AUTOSAR XML (schema 00044)
package /E40_Platform_System_SystemPackage/Components
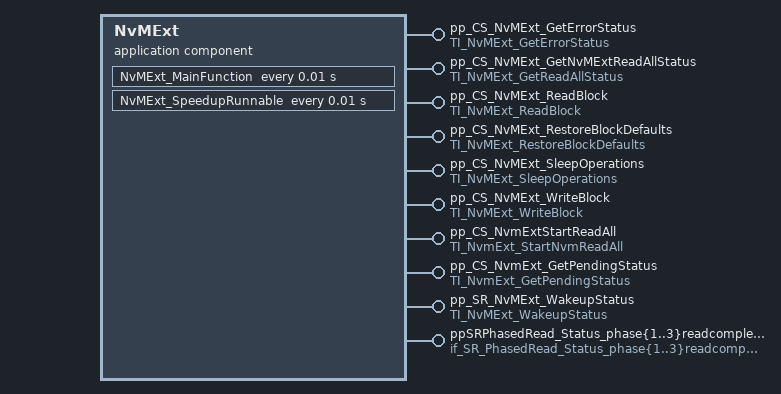
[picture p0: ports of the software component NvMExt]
  application sw component type NvMExt
    12 x provide port:
      pp_CS_NvMExt_GetErrorStatus: server-com-spec{operation=NvMExt_GetErrorStatus, queue-length=1}, provided-interface=TI_NvMExt_GetErrorStatus
      pp_CS_NvMExt_GetNvMExtReadAllStatus: server-com-spec{operation=NvmExt_GetNvMReadAllStatus, queue-length=1}, provided-interface=TI_NvMExt_GetReadAllStatus
      pp_CS_NvMExt_ReadBlock: server-com-spec{operation=NvMExt_ReadBlock, queue-length=1}, provided-interface=TI_NvMExt_ReadBlock
      pp_CS_NvMExt_RestoreBlockDefaults: server-com-spec{operation=NvMExt_RestoreBlockDefaults, queue-length=1}, provided-interface=TI_NvMExt_RestoreBlockDefaults
      pp_CS_NvMExt_SleepOperations: provided-interface=TI_NvMExt_SleepOperations
        provided-com-specs:
          operation=NvMExt_CancelSleep, queue-length=1
          operation=NvMExt_ReadytoSleep, queue-length=1
          operation=NvMExt_RequestSleep, queue-length=1
      pp_CS_NvMExt_WriteBlock: server-com-spec{operation=NvMExt_WriteBlock, queue-length=1}, provided-interface=TI_NvMExt_WriteBlock
      pp_CS_NvmExtStartReadAll: server-com-spec{operation=NvMExt_ReadAll, queue-length=1}, provided-interface=TI_NvmExt_StartNvmReadAll
      pp_CS_NvmExt_GetPendingStatus: server-com-spec{operation=NvMExt_GetPendingStatus, queue-length=1}, provided-interface=TI_NvmExt_GetPendingStatus
      pp_SR_NvMExt_WakeupStatus: nonqueued-sender-com-spec{data-element=WakeupFlag, init-value=constant-reference=NvMExtWakeupFlagValue0}, provided-interface=TI_NvMExt_WakeupStatus
      ppSRPhasedRead_Status_phase{1..3}readcompleted: nonqueued-sender-com-spec{data-element=PhasedRead_Status_phase{1..3}readcompleted, init-value=constant-reference=NvMExtPhasedRead_Status_phase{1..3}readcompletedValue0}, provided-interface=if_SR_PhasedRead_Status_phase{1..3}readcompleted
    behavior IB_NvMExt
      timing event TENvMExt_MainFunction: start-on-event=NvMExt_MainFunction, period=0.01
      10 x operation invoked event:
        OIE_pp_CS_NvMExt_SleepOperations_NvMExt_CancelSleepTrigByNvMExt_CancelSleep: start-on-event=NvMExt_CancelSleep, operation=pp_CS_NvMExt_SleepOperations.NvMExt_CancelSleep
        OIE_pp_CS_NvMExt_GetErrorStatus_NvMExt_GetErrorStatusTrigByNvMExt_GetErrorStatus: start-on-event=NvMExt_GetErrorStatus, operation=pp_CS_NvMExt_GetErrorStatus.NvMExt_GetErrorStatus
        OIE_pp_CS_NvmExt_GetPendingStatus_NvMExt_GetPendingStatusTrigByNvMExt_GetPendingStatus: start-on-event=NvMExt_GetPendingStatus, operation=pp_CS_NvmExt_GetPendingStatus.NvMExt_GetPendingStatus
        OIE_pp_CS_NvmExtStartReadAll_NvMExt_ReadAllTrigByNvMExt_ReadAll: start-on-event=NvMExt_ReadAll, operation=pp_CS_NvmExtStartReadAll.NvMExt_ReadAll
        OIE_pp_CS_NvMExt_ReadBlock_NvMExt_ReadBlockTrigByNvMExt_ReadBlock: start-on-event=NvMExt_ReadBlock, operation=pp_CS_NvMExt_ReadBlock.NvMExt_ReadBlock
        OIE_pp_CS_NvMExt_SleepOperations_NvMExt_ReadytoSleepTrigByNvMExt_ReadytoSleep: start-on-event=NvMExt_ReadytoSleep, operation=pp_CS_NvMExt_SleepOperations.NvMExt_ReadytoSleep
        OIE_pp_CS_NvMExt_SleepOperations_NvMExt_RequestSleepTrigByNvMExt_RequestSleep: start-on-event=NvMExt_RequestSleep, operation=pp_CS_NvMExt_SleepOperations.NvMExt_RequestSleep
        OIE_pp_CS_NvMExt_RestoreBlockDefaults_NvMExt_RestoreBlockDefaultsTrigByNvMExt_RestoreBlockDefaults: start-on-event=NvMExt_RestoreBlockDefaults, operation=pp_CS_NvMExt_RestoreBlockDefaults.NvMExt_RestoreBlockDefaults
        OIE_pp_CS_NvMExt_WriteBlock_NvMExt_WriteBlockTrigByNvMExt_WriteBlock: start-on-event=NvMExt_WriteBlock, operation=pp_CS_NvMExt_WriteBlock.NvMExt_WriteBlock
        OIE_pp_CS_NvMExt_GetNvMExtReadAllStatus_NvmExt_GetNvMReadAllStatusTrigByNvmExt_GetNvMReadAllStatus: start-on-event=NvmExt_GetNvMReadAllStatus, operation=pp_CS_NvMExt_GetNvMExtReadAllStatus.NvmExt_GetNvMReadAllStatus
      timing event TENvMExt_SpeedupRunnable: start-on-event=NvMExt_SpeedupRunnable, period=0.01
      port-api-options:
        enable-take-address=false, indirect-api=false, port=pp_CS_NvMExt_GetErrorStatus
        enable-take-address=false, indirect-api=false, port=pp_CS_NvMExt_GetNvMExtReadAllStatus
        enable-take-address=false, indirect-api=false, port=pp_CS_NvMExt_ReadBlock
        enable-take-address=false, indirect-api=false, port=pp_CS_NvMExt_RestoreBlockDefaults
        enable-take-address=false, indirect-api=false, port=pp_CS_NvMExt_SleepOperations
        enable-take-address=false, indirect-api=false, port=pp_CS_NvMExt_WriteBlock
        enable-take-address=false, indirect-api=false, port=pp_CS_NvmExtStartReadAll
        enable-take-address=false, indirect-api=false, port=pp_CS_NvmExt_GetPendingStatus
        enable-take-address=false, indirect-api=false, port=pp_SR_NvMExt_WakeupStatus
        enable-take-address=false, indirect-api=false, port=ppSRPhasedRead_Status_phase{1..3}readcompleted
      12 x runnable, all with can-be-invoked-concurrently=true:
        NvMExt_MainFunction
          data-send-points:
            4 x access:
              DWA_pp_SR_NvMExt_WakeupStatus_WakeupFlag: accessed-variable=pp_SR_NvMExt_WakeupStatus.WakeupFlag
              DWA_ppSRPhasedRead_Status_phase{1..3}readcompleted_PhasedRead_Status_phase{1..3}readcompleted: accessed-variable=ppSRPhasedRead_Status_phase{1..3}readcompleted.PhasedRead_Status_phase{1..3}readcompleted
        NvMExt_CancelSleep
        NvMExt_GetErrorStatus
          data-send-points:
            4 x access:
              DWA_pp_SR_NvMExt_WakeupStatus_WakeupFlag: accessed-variable=pp_SR_NvMExt_WakeupStatus.WakeupFlag
              DWA_ppSRPhasedRead_Status_phase{1..3}readcompleted_PhasedRead_Status_phase{1..3}readcompleted: accessed-variable=ppSRPhasedRead_Status_phase{1..3}readcompleted.PhasedRead_Status_phase{1..3}readcompleted
        NvMExt_GetPendingStatus
        NvMExt_ReadAll
        NvMExt_ReadBlock
          data-send-points:
            4 x access:
              DWA_pp_SR_NvMExt_WakeupStatus_WakeupFlag: accessed-variable=pp_SR_NvMExt_WakeupStatus.WakeupFlag
              DWA_ppSRPhasedRead_Status_phase{1..3}readcompleted_PhasedRead_Status_phase{1..3}readcompleted: accessed-variable=ppSRPhasedRead_Status_phase{1..3}readcompleted.PhasedRead_Status_phase{1..3}readcompleted
        NvMExt_ReadytoSleep
        NvMExt_RequestSleep
        NvMExt_RestoreBlockDefaults
          data-send-points:
            4 x access:
              DWA_pp_SR_NvMExt_WakeupStatus_WakeupFlag: accessed-variable=pp_SR_NvMExt_WakeupStatus.WakeupFlag
              DWA_ppSRPhasedRead_Status_phase{1..3}readcompleted_PhasedRead_Status_phase{1..3}readcompleted: accessed-variable=ppSRPhasedRead_Status_phase{1..3}readcompleted.PhasedRead_Status_phase{1..3}readcompleted
        NvMExt_WriteBlock
          data-send-points:
            4 x access:
              DWA_pp_SR_NvMExt_WakeupStatus_WakeupFlag: accessed-variable=pp_SR_NvMExt_WakeupStatus.WakeupFlag
              DWA_ppSRPhasedRead_Status_phase{1..3}readcompleted_PhasedRead_Status_phase{1..3}readcompleted: accessed-variable=ppSRPhasedRead_Status_phase{1..3}readcompleted.PhasedRead_Status_phase{1..3}readcompleted
        NvmExt_GetNvMReadAllStatus
        NvMExt_SpeedupRunnable
  swc implementation IMPL_NvMExt: behavior=IB_NvMExt
